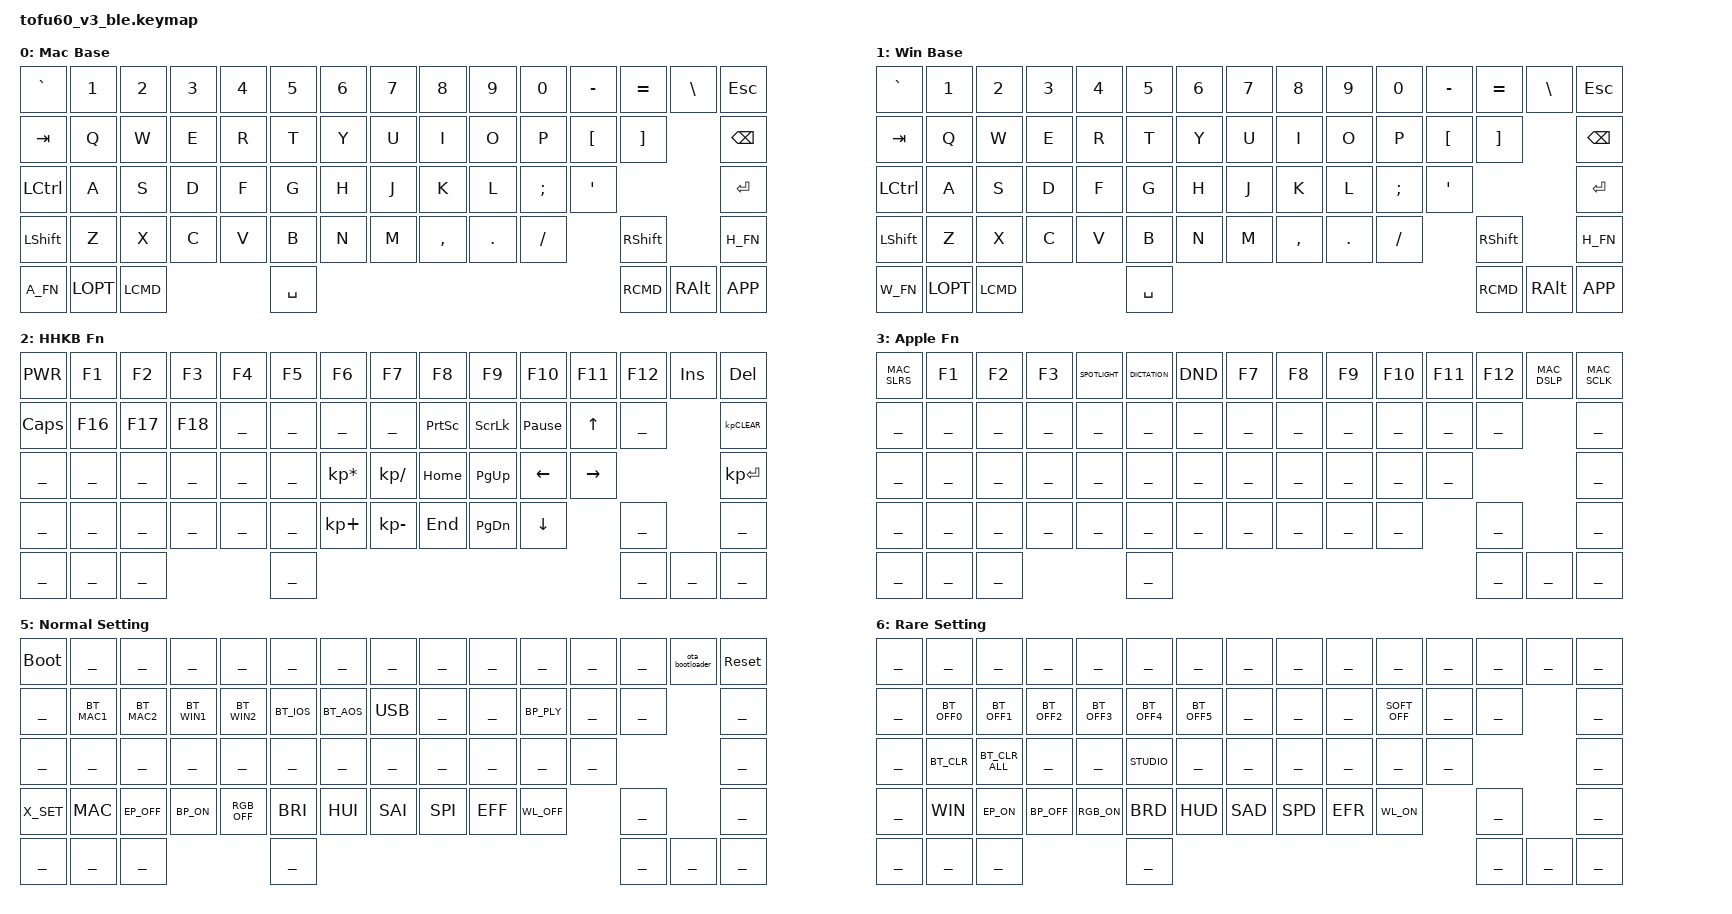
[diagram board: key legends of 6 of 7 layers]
#include "my-keymap-common.dtsi"

/ {
  keymap {
    compatible = "zmk,keymap";
    mac_base_layer {
      display-name = "Mac Base";
      // -------------------------------------------------------------------------------------------
      // |  `  |  1  |  2  |  3  |  4  |  5  |  6  |  7  |  8  |  9  |  0  |  -  |  =  |  \  | ESC |
      // -------------------------------------------------------------------------------------------
      // | TAB    |  Q  |  W  |  E  |  R  |  T  |  Y  |  U  |  I  |  O  |  P  |  [  |  ]  | Bkspc  |
      // -------------------------------------------------------------------------------------------
      // | CAPS     |  A  |  S  |  D  |  F  |  G  |  H  |  J  |  K  |  L  |  ;  |  '  |     ENTER  |
      // -------------------------------------------------------------------------------------------
      // |  SHIFT     |  Z  |  X  |  C  |  V  |  B  |  N  |  M  |  ,  |  .  |  /  |  SHIFT   | MO2 |
      // ------------------------------------------------------------------------------------------
      // |  fn   | Opt |  Cmd  |            SPACE                          |  Cmd   | Opt |  App   |
      // -------------------------------------------------------------------------------------------
      bindings =
        <
         &kp GRAVE  &kp N1  &kp N2  &kp N3  &kp N4  &kp N5  &kp N6  &kp N7  &kp N8     &kp N9   &kp N0    &kp MINUS  &kp EQUAL  &kp BSLH  &kp ESC
         &kp TAB    &kp Q   &kp W   &kp E   &kp R   &kp T   &kp Y   &kp U   &kp I      &kp O    &kp P     &kp LBKT   &kp RBKT             &kp BSPC
         &kp LCTRL  &kp A   &kp S   &kp D   &kp F   &kp G   &kp H   &kp J   &kp K      &kp L    &kp SEMI  &kp SQT                         &kp RET
         &kp LSHFT  &kp Z   &kp X   &kp C   &kp V   &kp B   &kp N   &kp M   &kp COMMA  &kp DOT  &kp FSLH             &kp RSHIFT           _H_FN
         _A_FN      _LOPT  _LCMD                    &kp SPACE                                                        _RCMD      &kp RALT  _APP
        >;
    };
    win_base_layer {
      display-name = "Win Base";
      bindings =
        <
         &kp GRAVE  &kp N1  &kp N2  &kp N3  &kp N4  &kp N5  &kp N6  &kp N7  &kp N8     &kp N9   &kp N0    &kp MINUS  &kp EQUAL  &kp BSLH  &kp ESC
         &kp TAB    &kp Q   &kp W   &kp E   &kp R   &kp T   &kp Y   &kp U   &kp I      &kp O    &kp P     &kp LBKT   &kp RBKT             &kp BSPC
         &kp LCTRL  &kp A   &kp S   &kp D   &kp F   &kp G   &kp H   &kp J   &kp K      &kp L    &kp SEMI  &kp SQT                         &kp RET
         &kp LSHFT  &kp Z   &kp X   &kp C   &kp V   &kp B   &kp N   &kp M   &kp COMMA  &kp DOT  &kp FSLH             &kp RSHIFT           _H_FN
         _W_FN      _LOPT   _LCMD                   &kp SPACE                                             _RCMD      &kp RALT             _APP
        >;
    };
    hhkb_fn_layer {
      display-name = "HHKB Fn";
      bindings =
        <
         &kp K_PWR  &kp F1     &kp F2   &kp F3   &kp F4  &kp F5  &kp F6           &kp F7         &kp F8     &kp F9     &kp F10          &kp F11   &kp F12  &kp INS  &kp DEL
         &kp CAPS   &kp F16    &kp F17  &kp F18  ______  ______  ______           ______         &kp PSCRN  &kp SLCK   &kp PAUSE_BREAK  &kp UP    ______            &kp KP_CLEAR
         ______     ______     ______   ______   ______  ______  &kp KP_MULTIPLY  &kp KP_DIVIDE  &kp HOME   &kp PG_UP  &kp LEFT         &kp RIGHT                   &kp KP_ENTER
         ______     ______     ______   ______   ______  ______  &kp KP_PLUS      &kp KP_MINUS   &kp END    &kp PG_DN  &kp DOWN                   ______            ______
         ______     ______     ______                                             ______                                                ______    ______            ______
        >;
    };
    apple_fn_layer {
      display-name = "Apple Fn";
      bindings =
        <
         _MAC_SLRS  &kp F1  &kp F2  &kp F3  _SPOTLIGHT _DICTATION  _DND    &kp F7  &kp F8  &kp F9  &kp F10  &kp F11  &kp F12  _MAC_DSLP  _MAC_SCLK
         ______     ______  ______  ______  ______     ______      ______  ______  ______  ______  ______   ______   ______              ______
         ______     ______  ______  ______  ______     ______      ______  ______  ______  ______  ______   ______                       ______
         ______     ______  ______  ______  ______     ______      ______  ______  ______  ______  ______            ______              ______
         ______     ______  ______                                 ______                                   ______   ______              ______
        >;
    };
    win_fn_layer {
      display-name = "Win Fn";
      bindings =
        <
         ______  _FN_F1  _FN_F2  _FN_F3  _FN_F4  _FN_F5  _FN_F6  _FN_F7  _FN_F8  _FN_F9  _FN_F10 _FN_F11 _FN_F12  ______  _WIN_SCLK
         ______  _FN_Q   ______  _FN_E   ______  ______  ______  ______  ______  ______  ______  ______  ______           _FN_BS
         ______  _FN_A   ______  ______  _FN_F   ______  _FN_H   ______  ______  ______  ______  ______                   ______
         ______  ______  ______  _FN_C   ______  ______  _FN_N   _FN_M   ______  ______  ______          ______           ______
         ______  ______  ______                                  _FN_SPC                 ______  ______
        >;
    };
    normal_setting_layer {
      display-name = "Normal Setting";
      bindings =
        <
         &bootloader  ______    ______    ______    ______    ______    ______   ______  ______  ______  ______  ______  ______  &ota_bootloader  &sys_reset
         ______       _BT_MAC1  _BT_MAC2  _BT_WIN1  _BT_WIN2  _BT_IOS   _BT_AOS  _USB    ______  ______  _BP_PLY ______  ______                   ______
         ______      ______     ______    ______    ______    ______    ______   ______  ______  ______  ______  ______                           ______
         _X_SET       _MAC      _EP_OFF   _BP_ON    _RGB_OFF  _BRI      _HUI     _SAI    _SPI    _EFF    _WL_OFF         ______                   ______
         ______       ______    ______                                  ______                                   ______  ______                   ______
        >;
    };
    rare_setting_layer {
      display-name = "Rare Setting";
      bindings =
        <
         ______  ______    ______       ______    ______    ______    ______   ______  ______  ______  ______    ______  ______  ______  ______
         ______  _BT_OFF0  _BT_OFF1     _BT_OFF2  _BT_OFF3  _BT_OFF4  _BT_OFF5 ______  ______  ______  _SOFT_OFF ______  ______          ______
         ______  _BT_CLR   _BT_CLR_ALL  ______    ______    _STUDIO   ______   ______  ______  ______  ______    ______                  ______
         ______  _WIN      _EP_ON       _BP_OFF   _RGB_ON   _BRD      _HUD     _SAD    _SPD    _EFR    _WL_ON            ______          ______
         ______  ______    ______                                     ______                                     ______  ______          ______
        >;
    };
  };
};
